# IWRL6432 register map
File version: 1.0
CPU: CM4 1.0, other endian, MPU, FPU, 3 interrupt priority bits
Registers are 32-bit, read-write, reset 0x0 unless marked. A register's access mark holds for its fields unless they carry their own. Offsets are from the block's base; [hi:lo] are bit positions.

## APP_UART_0 — APP_UART
Base 0x53F7F000
Same registers: APP_UART_1 0x57F7F000
0x00 SCIGCR0 — The SCIGCR0 register defines the module reset
  [0] RESET — [0:0] GIO reset
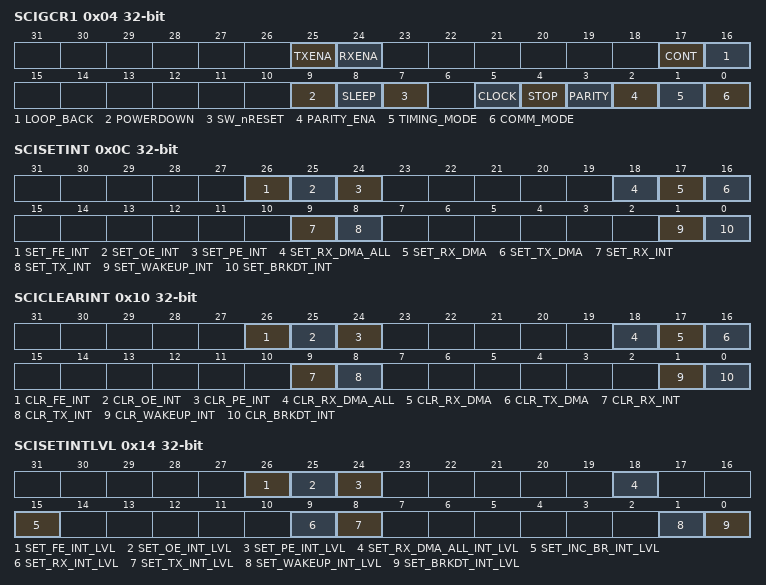
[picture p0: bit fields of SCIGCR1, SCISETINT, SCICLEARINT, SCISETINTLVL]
0x04 SCIGCR1 — The SCIGCR1 register defines the frame format, protocol, and communication mode used by the SCI
  [25] TXENA — [25:25] Data is transferred from SCITD to SCITXSHF only when the TXENA bit is set
  [24] RXENA — [24:24] Allows the receiver to transfer data from the shift buffer to the receive buffer
  [17] CONT — [17:17] This bit has an effect only when a program is being debugged with an emulator, and it determines how the SCI operates when the program is suspended
  [16] LOOP_BACK — [16:16] Enable bit for loopback mode
  [9] POWERDOWN — [9:9] When the POWERDOWN bit is set, the SCI attempts to enter local low-power mode
  [8] SLEEP — [8:8] In a multiprocessor configuration, this bit controls the receive sleep function. Clearing this bit brings the SCI out of sleep mode
  [7] SW_nRESET — [7:7] Software reset (active low)
  [5] CLOCK — [5:5] SCI internal clock enable
  [4] STOP — [4:4] SCI number of stop bits
  [3] PARITY — [3:3] SCI parity odd/even selection
  [2] PARITY_ENA — [2:2] SCI parity enable
  [1] TIMING_MODE — [1:1] SCI timing mode bit (0=Isosynchronous timing,1=Asynchronous timing)
  [0] COMM_MODE — [0:0] SCI communication mode bit (0=Idle-line mode, 1=Address-bit mode)
0x0C SCISETINT — SCI Set Interrupt Register
  [26] SET_FE_INT — [26:26] Set Framing-Error Interrupt User and privilege mode (read): 0 = Interrupt is disabled 1 = Interrupt is enabled User and privilege mode (write): 0 = leaves the corresponding bit unchanged 1 = enable interrupt
  [25] SET_OE_INT — [25:25] Set Overrun-Error Interrupt User and privilege mode (read): 0 = Interrupt is disabled 1 = Interrupt is enabled User and privilege mode (write): 0 = leaves the corresponding bit unchanged 1 = enable interrupt
  [24] SET_PE_INT — [24:24] Set Parity Interrupt User and privilege mode (read): 0 = Interrupt is disabled 1 = Interrupt is enabled User and privilege mode (write): 0 = leaves the corresponding bit unchanged 1 = enable interrupt
  [18] SET_RX_DMA_ALL — [18:18] Determines if a separate interrupt is generated for the address frames sent in multiprocessor communications User and privilege mode (read): 0 = DMA request is disabled for address frames (RX interrupt request is enabled for address frames) 1 = DMA request is enabled for address and data frames User and privilege mode (write): 0 = leaves the corresponding bit unchanged 1 = enable DMA request for address and data frames
  [17] SET_RX_DMA — [17:17] To select receiver DMA requests, this bit must be set. If it is cleared, interrupt requests are generated depending on bit SCISETINT.9 User and privilege mode (read): 0 = DMA request is disabled 1 = DMA request is enabled Privilege mode (write): 0 = leaves the corresponding bit unchanged 1 = enable DMA request
  [16] SET_TX_DMA — [16:16] To select DMA requests for the transmitter, this bit must be set. If it is cleared, interrupt requests are generated depending on SET TX INT bit (SCISETINT.8) User and privilege mode (read): 0 = TX interrupt request selected 1 = TX DMA request selected User and privilege mode (write): 0 = leaves the corresponding bit unchanged 1 = enable interrupt
  [9] SET_RX_INT — [9:9] Receiver interrupt enable:Setting this bit enables the SCI to generate a receive interrupt after a frame has been completely received and the data is being transferred from SCIRXSHF to SCIRD. User and privilege mode (read): 0 = Interrupt is disabled 1 = Interrupt is enabled User and privilege mode (write): 0 = leaves the corresponding bit unchanged 1 = enable interrupt
  [8] SET_TX_INT — [8:8] Set Transmitter interrupt. Setting this bit enables the SCI to generate a transmit interrupt as data is being transferred from SCITD to SCITXSHF and the TXRDY bit is being set. User and privilege mode (read): 0 = Interrupt is disabled 1 = Interrupt is enabled User and privilege mode (write): 0 = leaves the corresponding bit unchanged 1 = enable interrupt
  [1] SET_WAKEUP_INT — [1:1] Set Wake-up interrupt User and privilege mode (read): 0 = Interrupt is disabled 1 = Interrupt is enabled User and privilege mode (write): 0 = leaves the corresponding bit unchanged 1 = enable interrupt
  [0] SET_BRKDT_INT — [0:0] Set Break-detect interrupt. Setting this bit enables the SCI to generate an error interrupt if a break condition is detected on the SCIRX pin. User and privilege mode (read): 0 = Interrupt is disabled 1 = Interrupt is enabled User and privilege mode (write): 0 = leaves the corresponding bit unchanged 1 = enable interrupt
0x10 SCICLEARINT — SCI Clear Interrupt Register
  [26] CLR_FE_INT — [26:26] Clear Framing-Error Interrupt: Setting this bit disables the SCI module to generate an interrupt when there is a Framing error. User and privilege mode (read): 0 = Interrupt is disabled 1 = Interrupt is enabled User and privilege mode (write): 0 = leaves the corresponding bit unchanged 1 = disable interrupt
  [25] CLR_OE_INT — [25:25] Clear Overrun-Error Interrupt. This bit disables the SCI overrun interrupt when set. User and privilege mode (read): 0 = Interrupt is disabled 1 = Interrupt is enabled User and privilege mode (write): 0 = leaves the corresponding bit unchanged 1 = disable interrupt
  [24] CLR_PE_INT — [24:24] Clear Parity Interrupt. Setting this bit disables the SCI Parity error interrupt. User and privilege mode (read): 0 = Interrupt is disabled 1 = Interrupt is enabled User and privilege mode (write): 0 = leaves the corresponding bit unchanged 1 = enable interrupt
  [18] CLR_RX_DMA_ALL — [18:18] User and privilege mode (read): 0 = DMA request is disabled for address frames (RX interrupt request is enabled for address frames). DMA request is enabled for data frames. 1 = DMA request is enabled for address and data frames User and privilege mode (write): 0 = leaves the corresponding bit unchanged 1 = disable DMA request for address frames
  [17] CLR_RX_DMA — [17:17] Clear RX DMA request. This bit disalbes the receive DMA request when set. User and privilege mode (read): 0 = DMA request is disabled 1 = DMA request is enabled User and privilege mode (write): 0 = leaves the corresponding bit unchanged 1 = disable DMA request
  [16] CLR_TX_DMA — [16:16] Clear TX DMA request. This bit disables the transmit DMA request when set. User and privilege mode (read): 0 = DMA request is disabled 1 = DMA request is enabled User and privilege mode (write): 0 = leaves the corresponding bit unchanged 1 = disable DMA request
  [9] CLR_RX_INT — [9:9] Clear Receiver interrupt. This bit disables the receiver interrupt when set. User and privilege mode (read): 0 = Interrupt is disabled 1 = Interrupt is enabled Privilege mode (write): 0 = leaves the corresponding bit unchanged 1 = disable interrupt
  [8] CLR_TX_INT — [8:8] Clear Transmitter interrupt. This bit disables the transmitter interrupt when set. User and privilege mode (read): 0 = Interrupt is disabled 1 = Interrupt is enabled User and privilege mode (write): 0 = leaves the corresponding bit unchanged 1 = disable interrupt
  [1] CLR_WAKEUP_INT — [1:1] Clear Wake-up interrupt. This bit disables the wakeup interrupt when set. User and privilege mode (read): 0 = Interrupt is disabled 1 = Interrupt is enabled User and privilege mode (write): 0 = leaves the corresponding bit unchanged 1 = disable interrupt
  [0] CLR_BRKDT_INT — [0:0] Clear Break-detect interrupt. This bit disables the Break-detect interrupt when set. User and privilege mode (read): 0 = Interrupt is disabled 1 = Interrupt is enabled User and privilege mode (write): 0 = leaves the corresponding bit unchanged 1 = disable interrupt
0x14 SCISETINTLVL — SCI Set Interrupt Level Register
  [26] SET_FE_INT_LVL — [26:26] Clear Framing-Error Interrupt Level. User and privilege mode (read): 0 = Interrupt level mapped to INT0 line 1 = Interrupt level mapped to INT1 line User and privilege mode (write): 0 = Leaves the corresponding bit unchanged 1 = Clear interrupt level to line INT1
  [25] SET_OE_INT_LVL — [25:25] Clear Overrun-Error Interrupt Level. User and privilege mode (read): 0 = Interrupt level mapped to INT0 line 1 = Interrupt level mapped to INT1 line User and privilege mode (write): 0 = Leaves the corresponding bit unchanged 1 = Clear interrupt level to line INT1
  [24] SET_PE_INT_LVL — [24:24] Clear Parity Error Interrupt Level. User and privilege mode (read): 0 = Interrupt level mapped to INT0 line 1 = Interrupt level mapped to INT1 line User and privilege mode (write): 0 = Leaves the corresponding bit unchanged 1 = Clear interrupt level to line INT1
  [18] SET_RX_DMA_ALL_INT_LVL — [18:18] User and privilege mode (read): 0 = RX interrupt request for address frames mapped to INT0 line. 1 = RX interrupt request for address frames mapped to INT1 line. User and privilege mode (write): 0 = Leaves the corresponding bit unchanged 1 = Clear interrupt level to line INT1
  [15] SET_INC_BR_INT_LVL — [15:15] Reserved
  [9] SET_RX_INT_LVL — [9:9] Clear Receiver interrupt Level. User and privilege mode (read): 0 = Interrupt level mapped to INT0 line 1 = Interrupt level mapped to INT1 line User and privilege mode (write): 0 = Leaves the corresponding bit unchanged 1 = Clear interrupt level to line INT1
  [8] SET_TX_INT_LVL — [8:8] Clear Transmitter interrupt Level. User and privilege mode (read): 0 = Interrupt level mapped to INT0 line 1 = Interrupt level mapped to INT1 line User and privilege mode (write): 0 = Leaves the corresponding bit unchanged 1 = Clear interrupt level to line INT1
  [1] SET_WAKEUP_INT_LVL — [1:1] Clear Wake-up interrupt Level. User and privilege mode (read): 0 = Interrupt level mapped to INT0 line 1 = Interrupt level mapped to INT1 line User and privilege mode (write): 0 = Leaves the corresponding bit unchanged 1 = Clear interrupt level to line INT1
  [0] SET_BRKDT_INT_LVL — [0:0] Clear Break-detect interrupt Level. User and privilege mode (read): 0 = Interrupt level mapped to INT0 line 1 = Interrupt level mapped to INT1 line User and privilege mode (write): 0 = Leaves the corresponding bit unchanged 1 = Clear interrupt level to line INT1
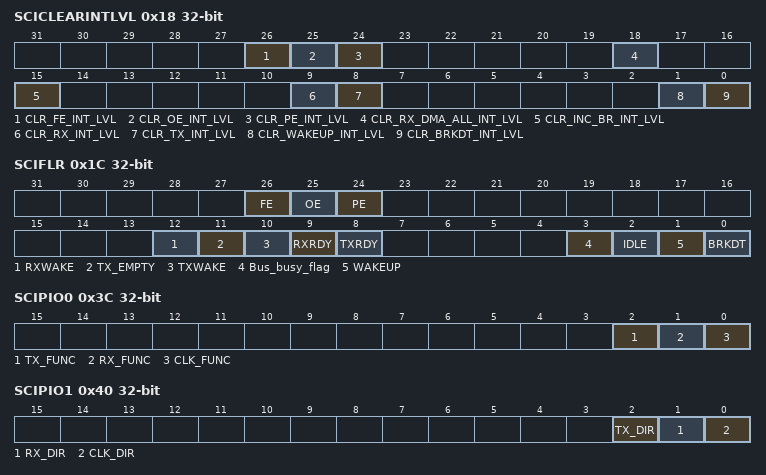
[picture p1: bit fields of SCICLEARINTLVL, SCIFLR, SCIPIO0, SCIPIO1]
0x18 SCICLEARINTLVL — SCI Clear Interrupt Level Register
  [26] CLR_FE_INT_LVL — [26:26] Clear Framing-Error Interrupt Level. User and privilege mode (read): 0 = Interrupt level mapped to INT0 line 1 = Interrupt level mapped to INT1 line User and privilege mode (write): 0 = Leaves the corresponding bit unchanged 1 = Reset interrupt level to line INT0
  [25] CLR_OE_INT_LVL — [25:25] Clear Framing-Error Interrupt Level. User and privilege mode (read): 0 = Interrupt level mapped to INT0 line 1 = Interrupt level mapped to INT1 line User and privilege mode (write): 0 = Leaves the corresponding bit unchanged 1 = Reset interrupt level to line INT0
  [24] CLR_PE_INT_LVL — [24:24] Clear Framing-Error Interrupt Level. User and privilege mode (read): 0 = Interrupt level mapped to INT0 line 1 = Interrupt level mapped to INT1 line User and privilege mode (write): 0 = Leaves the corresponding bit unchanged 1 = Reset interrupt level to line INT0
  [18] CLR_RX_DMA_ALL_INT_LVL — [18:18] Clear receive DMA ALL interrupt level. User and privilege mode (read): 0 = RX interrupt request for address frames is mapped to INT0 line. 1 = RX interrupt request for address frames is mapped to INT1 line. User and privilege mode (write): 0 = Leaves the corresponding bit unchanged. 1 = Reset interrupt level to line INT0.
  [15] CLR_INC_BR_INT_LVL
  [9] CLR_RX_INT_LVL — [9:9] Clear Receiver interrupt level. User and privilege mode (read): 0 = Interrupt level mapped to INT0 line 1 = Interrupt level mapped to INT1 line User and privilege mode (write): 0 = Leaves the corresponding bit unchanged 1 = Reset interrupt level to line INT0
  [8] CLR_TX_INT_LVL — [8:8] Clear Transmitter interrupt level. User and privilege mode (read): 0 = Interrupt level mapped to INT0 line 1 = Interrupt level mapped to INT1 line User and privilege mode (write): 0 = Leaves the corresponding bit unchanged 1 = Reset interrupt level to line INT0
  [1] CLR_WAKEUP_INT_LVL — [1:1] Clear Wake-up interrupt level. User and privilege mode (read): 0 = Interrupt level mapped to INT0 line 1 = Interrupt level mapped to INT1 line User and privilege mode (write): 0 = Leaves the corresponding bit unchanged 1 = Reset interrupt level to line INT0
  [0] CLR_BRKDT_INT_LVL — [0:0] Clear Break-detect interrupt level. User and privilege mode (read): 0 = Interrupt level mapped to INT0 line 1 = Interrupt level mapped to INT1 line User and privilege mode (write): 0 = Leaves the corresponding bit unchanged 1 = Reset interrupt level to line INT0
0x1C SCIFLR — SCI Flags Register
  [26] FE — [26:26] SCI framing error flag Read: 0=No framing error detected 1=Framing error detected Write: 0=No effect 1=Clears this bit to 0
  [25] OE — [25:25] SCI overrun error flag This bit is set when the transfer of data from SCIRXSHF to SCIRD overwrites unread data already in SCIRD
  [24] PE — [24:24] SCI parity error flag. This bit is set when a parity error is detected in the received data
  [12] RXWAKE — [12:12] Receiver wake-up detect flag. The SCI sets this bit to indicate that the data currently in SCIRD is an address
  [11] TX_EMPTY — [11:11] Transmitter empty flag. The value of this flag indicates the contents of the transmitterΓÇÖs buffer register (SCITD) and shift register (SCITXSHF)
  [10] TXWAKE — [10:10] SCI transmitter wake-up method select. The TXWAKE bit controls whether the data in SCITD should be sent as an address or data frame using multiprocessor communication format
  [9] RXRDY — [9:9] SCI receiver ready flag. The receiver sets this bit to indicate that the SCIRD contains new data and is ready to be read by the CPU or DMA.
  [8] TXRDY — [8:8] Transmitter buffer register ready flag. When set, this bit indicates that the transmit buffer register (SCITD) is ready to receive another character.
  [3] Bus_busy_flag — [3:3] This bit indicates whether the receiver is in the process of receiving a frame.
  [2] IDLE — [2:2] SCI receiver in idle state. While this bit is set, the SCI looks for an idle period to resynchronize itself with the bit stream.
  [1] WAKEUP — [1:1] Wake-up flag. This bit is set by the SCI when receiver or transmitter activity has taken the module out of power-down mode.
  [0] BRKDT — [0:0] SCI break-detect flag. This bit is set when the SCI detects a break condition on the SCIRX pin.
0x20 SCIINTVECT0 — SCI Interrupt Offset Vector 0 Register
  [3:0] INTVECT0 — [3:0] Interrupt vector offset for INT0
0x24 SCIINTVECT1 — SCI Interrupt Offset Vector 1 Register
  [3:0] INTVECT1 — [3:0] Interrupt vector offset for INT1
0x28 SCICHAR — SCI Character Control Register
  [2:0] CHAR — [2:0] Sets the SCI data length from 1 to 8 bits
0x2C SCIBAUD — SCI Baud Rate Selection Register
  [23:0] BAUD — [23:0] SCI 24-bit baud selection
0x30 SCIED — Receiver Emulation Data Buffer
  [7:0] ED — [7:0] Receiver Emulation Data Buffer
0x34 SCIRD — Receiver Data Buffer
  [7:0] RD — [7:0] Contains received data.
0x38 SCITD — Transmit Data Buffer Register
  [7:0] TD — [7:0] Contains Data to be transmitted. This is pushed to SCITXSHF(shift register) when TXENA bit is set in SCRGCR1 register.
0x3C SCIPIO0 — SCI Pin I/O Control Register 0
  [2] TX_FUNC — [2:2] Defines the function of pin SCITX. 0=SCITX is a general-purpose digital I/O pin. 1=SCITX is the SCI transmit pin.
  [1] RX_FUNC — [1:1] Determines the data direction on the SCIRX pin if it is configured with general-purpose I/O functionality (RX FUNC = 0). See Table 12 for bit values. 0=SCIRX is a general-purpose input pin. 1=SCIRX is a general-purpose output pin
  [0] CLK_FUNC — [0:0] Clock function. Defines the function of pin SCICLK. 0=SCICLK is a general-purpose digital I/O pin. 1=SCICLK is the SCI serial clock pin.
0x40 SCIPIO1 — SCI Pin I/O Control Register 1
  [2] TX_DIR — [2:2] Determines the data direction on the SCITX pin if it is configured with general-purpose I/O functionality (TX FUNC = 0). See Table 11 for bit values. 0=SCITX is a general-purpose input pin. 1=SCITX is a general-purpose output pin
  [1] RX_DIR — [1:1] Determines the data direction on the SCIRX pin if it is configured with general-purpose I/O functionality (RX FUNC = 0). See Table 12 for bit values. 0=SCIRX is a general-purpose input pin. 1=SCIRX is a general-purpose output pin
  [0] CLK_DIR — [0:0] Clock data direction. Determines the data direction on the SCICLK pin. The direction is defined differently depending upon the value of the CLK FUNC bit 0=SCICLK is a general-purpose input pin. 1=SCICLK is a general-purpose output pin
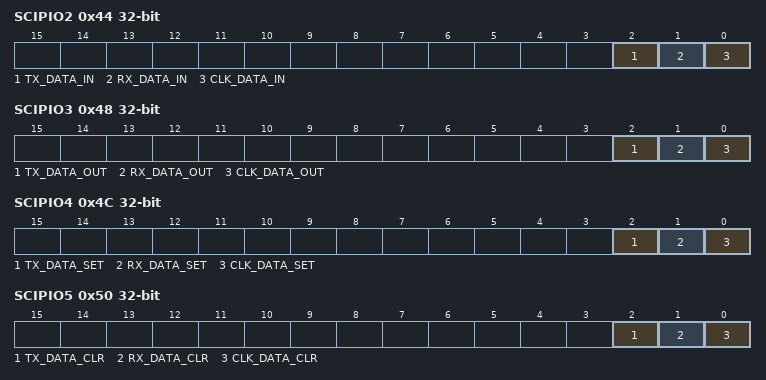
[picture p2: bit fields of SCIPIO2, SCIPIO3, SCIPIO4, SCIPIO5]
0x44 SCIPIO2 — SCI Pin I/O Control Register 2
  [2] TX_DATA_IN — [2:2] Contains current value on the SCITX pin. 0=SCITX value is logic low. 1=SCITX value is logic high.
  [1] RX_DATA_IN — [1:1] Contains current value on the SCIRX pin. 0=SCIRX value is logic low. 1=SCIRX value is logic high.
  [0] CLK_DATA_IN — [0:0] Contains the current value on pin SCICLK. 0=Pin SCICLK value is logic low. 1=Pin SCICLK value is logic high.
0x48 SCIPIO3 — SCI Pin I/O Control Register 3
  [2] TX_DATA_OUT — [2:2] Contains the data to be output on pin SCITX if the following conditions are met: TX FUNC = 0 (SCITX pin is a general-purpose I/O.) TX DATA DIR = 1 (SCITX pin is a general-purpose output.) 0=Output value on SCITX is a 0 (logic low). 1=Output value on SCITX is a 1 (logic high).
  [1] RX_DATA_OUT — [1:1] Contains the data to be output on pin SCIRX if the following conditions are met: RX FUNC = 0 (SCIRX pin is a general-purpose I/O.) RX DATA DIR = 1 (SCIRX pin is a general-purpose output.) 0=Output value on SCIRX is 0 (logic low). 1=Output value on SCIRX is 1 (logic high).
  [0] CLK_DATA_OUT — [0:0] Contains the data to be output on pin SCICLK if the following conditions are met: CLK FUNC = 0 (SCICLK pin is a general-purpose I/O.) CLK DATA DIR = 1 (SCICLK pin is a general-purpose output.) 0=Output value on SCICLK is a 0 (logic low). 1=Output value on SCICLK is a 1 (logic high).
0x4C SCIPIO4 — SCI Pin I/O Control Register 4
  [2] TX_DATA_SET — [2:2] Sets the data to be output on pin SCITX if the following conditions are met: TX FUNC = 0 (SCITX pin is a general-purpose I/O.) TX DIR = 1 (SCITX pin is a general-purpose output.)
  [1] RX_DATA_SET — [1:1] Sets the data to be output on pin SCIRX if the following conditions are met: RX FUNC = 0 (SCIRX pin is a general-purpose I/O.) RX DIR = 1 (SCIRX pin is a general-purpose output.)
  [0] CLK_DATA_SET — [0:0] Sets the data to be output on pin SCICLK if the following conditions are met: CLK FUNC = 0 (SCICLK pin is a general-purpose I/O.) CLK DIR = 1 (SCICLK pin is a general-purpose output.)
0x50 SCIPIO5 — SCI Pin I/O Control Register 5
  [2] TX_DATA_CLR — [2:2] Clears the data to be output on pin SCITX if the following conditions are met: TX FUNC = 0 (SCITX pin is a general-purpose I/O.) TX DIR = 1 (SCITX pin is a general-purpose output.)
  [1] RX_DATA_CLR — [1:1] Clears the data to be output on pin SCIRX if the following conditions are met: RX FUNC = 0 (SCITX pin is a general-purpose I/O.) RX DIR = 1 (SCITX pin is a general-purpose output.)
  [0] CLK_DATA_CLR — [0:0] Clears the data to be output on pin SCITX if the following conditions are met: TX FUNC = 0 (SCITX pin is a general-purpose I/O.) TX DIR = 1 (SCITX pin is a general-purpose output.)
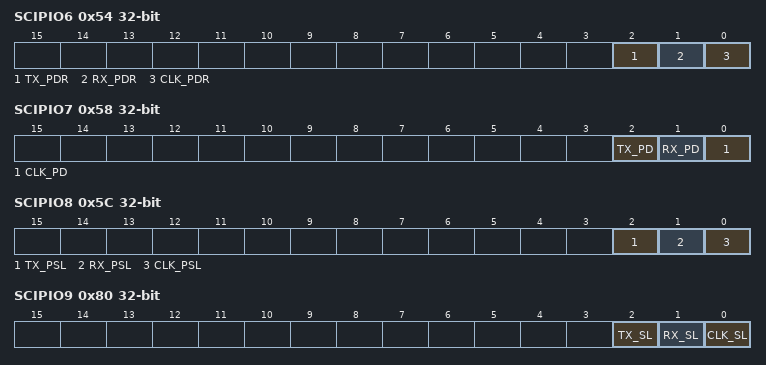
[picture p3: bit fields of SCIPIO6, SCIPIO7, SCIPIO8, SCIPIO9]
0x54 SCIPIO6 — SCI Pin I/O Control Register 6
  [2] TX_PDR — [2:2] TX Open Drain Enable Enables open-drain capability in the output pin SCITX if the following conditions are met: TX DATA DIR = 1 (SCITX pin is a general-purpose output.) TX DOUT = 1
  [1] RX_PDR — [1:1] RX Open Drain Enable Enables open-drain capability in the output pin SCIRX if the following conditions are met: RX DATA DIR = 1 (SCIRX pin is a general-purpose output.) RX DOUT = 1
  [0] CLK_PDR — [0:0] CLK Open Drain Enable Enables open-drain capability in the output pin SCICLK if the following conditions are met: CLK DATA DIR = 1 (SCICLK pin is a general-purpose output.) CLK DOUT = 1
0x58 SCIPIO7 — SCI Pin I/O Control Register 7
  [2] TX_PD — [2:2] TX pin Pull Control Disable Disables pull control capability in the output pin SCITX. 0=Pull Control on SCITX pin is enabled. 1=Pull Control on SCITX pin is disabled.
  [1] RX_PD — [1:1] RX pin Pull Control Disable Disables pull control capability in the output pin SCIRX. 0=Pull Control on SCIRX pin is enabled. 1=Pull Control on SCIRX pin is disabled.
  [0] CLK_PD — [0:0] CLK pin Pull Control Disable Disables pull control capability in the output pin SCICLK. 0=Pull Control on SCICLK pin is enabled. 1=Pull Control on SCICLK pin is disabled.
0x5C SCIPIO8 — SCI Pin I/O Control Register 8
  [2] TX_PSL — [2:2] TX pin Pull Select Selects pull type in the output pin SCITX. 0=Pull-Down is on SCITX pin. 1=Pull-Up is on SCITX pin.
  [1] RX_PSL — [1:1] RX pin Pull Select Selects pull type in the output pin SCIRX. 0=Pull-Down is on SCIRX pin. 1=Pull-Up is on SCIRX pin.
  [0] CLK_PSL — [0:0] CLK pin Pull Select Selects pull type in the output pin SCICLK. 0=Pull-Down is on SCICLK pin. 1=Pull-Up is on SCICLK pin.
0x80 SCIPIO9 — SCI Pin I/O Control Register 9
  [2] TX_SL — [2:2] This bit controls the slew rate for the SCITX pin. 0=The normal output buffer is used for SCITX pin 1=The output buffer with slew control is used for SCITX pin.
  [1] RX_SL — [1:1] This bit controls the slew rate for the SCIRX pin. 0=The normal output buffer is used for SCIRX pin 1=The output buffer with slew control is used for SCIRX pin
  [0] CLK_SL — [0:0] This bit controls the slew rate for the SCICLK pin. 0=The normal output buffer is used for SCICLK pin 1=The output buffer with slew control is used for SCICLK pin
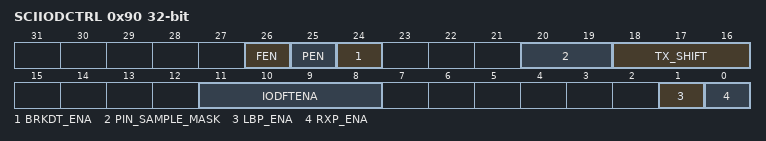
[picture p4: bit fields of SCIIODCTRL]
0x90 SCIIODCTRL — SCI IO DFT Control
  [26] FEN — [26:26] Frame Error Enable. User and Privileged Mode Reads and Writes: 1 = This bit is used to create a Frame Error. The stop bit received is ANDed with ΓÇÖ0ΓÇÖ and passed to the stop bit check circuitry. 0 = No effect.
  [25] PEN — [25:25] Parity Error Enable. User and Privileged Mode Reads and Writes: 1 = This bit is used to create a Parity Error. The parity bit received is toggled so that a parity error occurs. 0 = No effect
  [24] BRKDT_ENA — [24:24] Break Detect Error Enable. User and Privileged Mode Reads and Writes: 1 = This bit is used to create BRKDT Error. The stop bit of the frame is ANDed with ΓÇÿ0ΓÇÖ and passed to the RSM so that a frame error occurs. Then the RX pin is forced to continuous low for 10 TBITS so that a BRKDT error occurs. 0 = No effect.
  [20:19] PIN_SAMPLE_MASK — [20:19] PIN SAMPLE MASK These bits define the sample number at which the TX Pin value that is being transmitted will be inverted to verify the receive pin samples majority detection circuitry. PIN SAMPLE MASK: 00 -- No Mask, 01 -- Invert the TX Pin value at 7th SCLK, 10 -- Invert the TX Pin value at 8th SCLK, 11 -- Invert the TX Pin value at 9th SCLK.
  [18:16] TX_SHIFT — [18:16] These bits define the delay by which the value on TX pin is delayed so that the value on RX Pin is asynchronous. (Not applicable to Start Bit) TX SHIFT: 000 -- No Delay, 001 -- Delay by 1 SCLK, 010 -- Delay by 2 SCLKs, 011 -- Delay by 3 SCLKs, 100 -- Delay by 4 SCLKs, 101 -- Delay by 5 SCLKs, 110 -- Delay by 6 SCLKs, 111 -- No Delay.
  [11:8] IODFTENA — [11:8] These bits define the delay by which the value on TX pin is delayed so that the value on RX Pin is asynchronous. (Not applicable to Start Bit) TX SHIFT: 000 -- No Delay, 001 -- Delay by 1 SCLK, 010 -- Delay by 2 SCLKs, 011 -- Delay by 3 SCLKs, 100 -- Delay by 4 SCLKs, 101 -- Delay by 5 SCLKs, 110 -- Delay by 6 SCLKs, 111 -- No Delay.
  [1] LBP_ENA — [1:1] Module loopback enable. user and privileged mode reads: Write only in privileged mode: write/read : 1=Analog loopback is enabled in module I/O DFT mode(when IODFTENA = 1010) 0=Digital loopback is enabled.
  [0] RXP_ENA — [0:0] Module Analog loopback through receive pin enable. user and privileged mode reads: Write only in privileged mode: write/read : 1=Analog loopback through receive pin. 0=Analog loopback through transmit pin.
